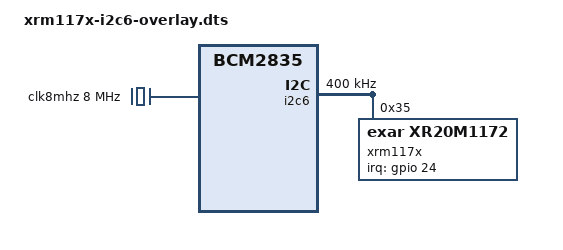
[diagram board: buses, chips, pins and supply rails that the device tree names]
/dts-v1/;
/plugin/;

/ {
    compatible = "brcm,bcm2835";

    fragment@0 {
        target = <&i2c6>;
        __overlay__ {
            status = "okay";
            #address-cells = <1>;
            #size-cells = <0>;
            clock-frequency = <400000>;

            xrm117x@35 {
                compatible = "exar,xr20m1172";
                reg = <0x35>;
                clocks = <&clk8mhz>;
                interrupt-parent = <&gpio>;
                interrupts = <24 2>;
                pinctrl-0 = <&xrm117x_pins>;
                pinctrl-names = "default";
                status = "okay";
                i2c-max-frequency = <400000>;
            };
        };
    };

    fragment@1 {
        target = <&gpio>;
        __overlay__ {
            xrm117x_pins: xrm117x_pins {
                brcm,pins = <24>;  // GPIO24
                brcm,function = <0>;  // Input function for interrupt
                brcm,pull = <0>; /* none */
            };
        };
    };

    fragment@2 {
        target = <&i2c6_pins>;
        __overlay__ {
            brcm,pins = <22 23>; // GPIO22 for SCL, GPIO23 for SDA
            brcm,function = <2>;   // BCM2835_FSEL_ALT5
            brcm,pull = <2>;       // BCM2835_PUD_UP
        };
    };

    fragment@3 {
        target-path = "/";
        __overlay__ {
            clk8mhz: oscillator {
                compatible = "fixed-clock";
                #clock-cells = <0>;
                clock-frequency = <8000000>;
            };
        };
    };

};
